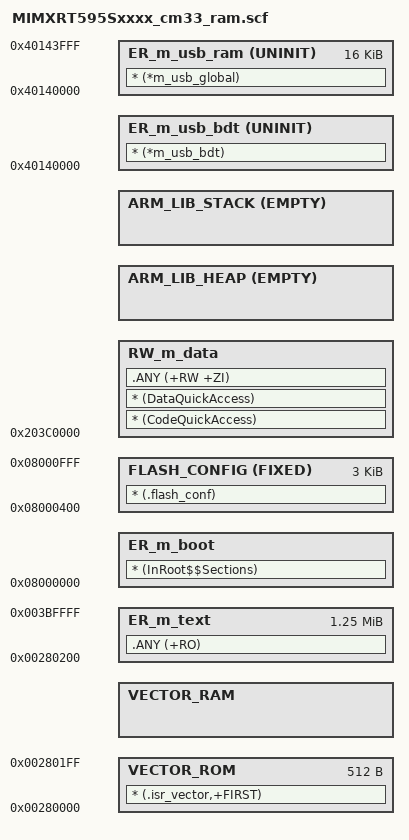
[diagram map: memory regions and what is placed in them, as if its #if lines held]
#!armclang --target=arm-arm-none-eabi -march=armv8-m.main -E -x c
/*
** ###################################################################
**     Processors:          MIMXRT595SFAWC_cm33
**                          MIMXRT595SFFOC_cm33
**
**     Compiler:            Keil ARM C/C++ Compiler
**     Reference manual:    iMXRT500RM Rev.0, 01/2021
**     Version:             rev. 5.0, 2021-07-28
**     Build:               b210730
**
**     Abstract:
**         Linker file for the Keil ARM C/C++ Compiler
**
**     Copyright 2016 Freescale Semiconductor, Inc.
**     Copyright 2016-2021 NXP
**     All rights reserved.
**
**     SPDX-License-Identifier: BSD-3-Clause
**
**     http:                 www.nxp.com
**     mail:                 support@nxp.com
**
** ###################################################################
*/


/* USB BDT size */
#define usb_bdt_size                   0x0
/* Sizes */
#if (defined(__stack_size__))
  #define Stack_Size                   __stack_size__
#else
  #define Stack_Size                   0x0400
#endif

#if (defined(__heap_size__))
  #define Heap_Size                    __heap_size__
#else
  #define Heap_Size                    0x0400
#endif

/* The SRAM region [0x10000-0x1BFFF] is reserved for ROM code. */
/* The SRAM region [0x0-0xFFFF], [0x1C000-0x1FFFF] are reserved for app-specific use cases. */
/* The SRAM region [0x20000-0x7FFFF] is reserved for Non-cached shared memory between M33 and DSP. */
/* The SRAM region [0x80000-0x27FFFF] is reserved for DSP code and data. */

#define  m_flash_start                 0x08000000

#define  m_boot_flash_conf_start       0x08000400
#define  m_boot_flash_conf_size        0x00000C00

#define  m_boot_interrupts_start       0x08001000

#define  m_interrupts_start            0x00280000
#define  m_interrupts_size             0x00000200

#define  m_text_start                  0x00280200
#define  m_text_size                   0x0013FE00

#define  m_data_start                  0x203C0000
#define  m_data_size                   0x00140000

#define  m_usb_sram_start              0x40140000
#define  m_usb_sram_size               0x00004000

LR_m_flash_conf m_flash_start m_boot_interrupts_start-m_flash_start {
  ER_m_boot m_flash_start { ; load address = execution address
    * (InRoot$$Sections)
  }
  FLASH_CONFIG m_boot_flash_conf_start FIXED m_boot_flash_conf_size { ; load address = execution address
    * (.flash_conf)
  }
}
LR_m_interrupts m_boot_interrupts_start m_interrupts_size+m_text_size {
  VECTOR_ROM m_interrupts_start m_interrupts_size {
    * (.isr_vector,+FIRST)
  }
  VECTOR_RAM +0 FILL 0x0 m_text_start-ImageLimit(VECTOR_ROM) {
  }
  ER_m_text m_text_start m_text_size {
    .ANY (+RO)
  }
  RW_m_data m_data_start ALIGN 4 m_data_size-Stack_Size-Heap_Size { ; RW data
    * (CodeQuickAccess)
    * (DataQuickAccess)
    .ANY (+RW +ZI)
  }

  ARM_LIB_HEAP +0 EMPTY Heap_Size {    ; Heap region growing up
  }
  ARM_LIB_STACK m_data_start+m_data_size EMPTY -Stack_Size { ; Stack region growing down
  }

  ER_m_usb_bdt m_usb_sram_start UNINIT usb_bdt_size {
    * (*m_usb_bdt)
  }

  ER_m_usb_ram (m_usb_sram_start + usb_bdt_size) UNINIT (m_usb_sram_size - usb_bdt_size) {
    * (*m_usb_global)
  }
}
